# CH32V203G6U6 register map
Vendor: WCH; File version: 0.1.0
CPU: QingKe V4B V4B, little endian, no MPU, no FPU, vendor SysTick, 4 interrupt priority bits
Registers are 16-bit, read-write, reset 0x0 unless marked. A register's access mark holds for its fields unless they carry their own. Offsets are from the block's base; [hi:lo] are bit positions; {n}, {i} and the like mark numbered series.

## BKP — Backup register block
Base 0x40006C00
{0x0+4i} DATAR{i} (i=1..10) — Backup data register (BKP_DR)
  [15:0] D — Backup data
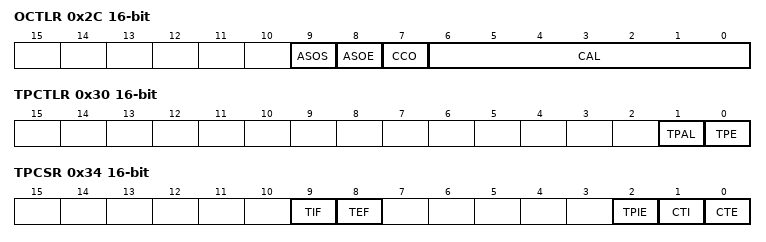
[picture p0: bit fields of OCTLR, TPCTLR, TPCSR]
0x2C OCTLR — RTC clock calibration register (BKP_OCTLR)
  [9] ASOS — Alarm or second output selection
  [8] ASOE — Alarm or second output enable
  [7] CCO — Calibration Clock Output
  [6:0] CAL — Calibration value
0x30 TPCTLR — Backup control register (BKP_TPCTLR)
  [1] TPAL — Tamper pin active level
  [0] TPE — Tamper pin enable
0x34 TPCSR — BKP_TPCSR control/status register (BKP_CSR)
  [9] TIF ro — Tamper Interrupt Flag
  [8] TEF ro — Tamper Event Flag
  [2] TPIE — Tamper Pin interrupt enable
  [1] CTI wo — Clear Tamper Interrupt
  [0] CTE wo — Clear Tamper event
{0x14+4i} DATAR{i} (i=11..42) — Backup data register (BKP_DR)
  [15:0] D — Backup data

## PWR — Power control block
Base 0x40007000
0x00 CTLR 32-bit — Power control register (PWR_CTRL)
  [8] DBP — Disable Backup Domain write protection
  [7] PLS_2V6
  [6] PLS_2V4
  [7:6] PLS_2V8
  [7:5] PLS — PVD Level Selection
  [5] PLS_2V3
  [6:5] PLS_2V5
  [7:5] PLS_2V9
  [4] PVDE — Power Voltage Detector Enable
  [3] CSBF — Clear STANDBY Flag
  [2] CWUF — Clear Wake-up Flag
  [1] PDDS — Power Down Deep Sleep
  [0] LPDS — Low Power Deep Sleep
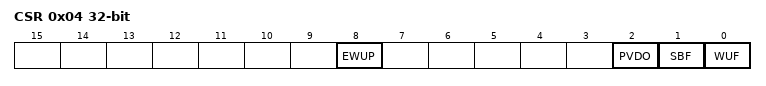
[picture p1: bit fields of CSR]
0x04 CSR 32-bit — Power control register (PWR_CSR)
  [8] EWUP — Enable WKUP pin
  [2] PVDO ro — PVD Output
  [1] SBF ro — STANDBY Flag
  [0] WUF ro — Wake-Up Flag

## AFIO — Alternate-function and pin remap controller
Base 0x40010000
0x00 ECR 32-bit — Event Control Register (AFIO_ECR)
  [26] PCFR1_SWJ_CFG_DISABLE
  [25] PCFR1_SWJ_CFG_JTAGDISABLE
  [26:24] PCFR1_SWJ_CFG
  [24] PCFR1_SWJ_CFG_NOJNTRST
  [20] PCFR1_ADC2_ETRGREG_REMAP
  [19] PCFR1_ADC2_ETRGINJ_REMAP
  [18] PCFR1_ADC1_ETRGREG_REMAP
  [17] PCFR1_ADC1_ETRGINJ_REMAP
  [16] PCFR1_TIM5CH4_IREMAP
  [15] PCFR1_PD01_REMAP
  [14] PCFR1_CAN_REMAP_REMAP2
  [14:13] PCFR1_CAN_REMAP
  [14:13] PCFR1_CAN_REMAP_REMAP3
  [12] PCFR1_TIM4_REMAP
  [11] PCFR1_TIM3_REMAP_PARTIALREMAP
  [11:10] PCFR1_TIM3_REMAP
  [11:10] PCFR1_TIM3_REMAP_FULLREMAP
  [9] PCFR1_TIM2_REMAP_PARTIALREMAP2
  [9:8] PCFR1_TIM2_REMAP
  [8] PCFR1_TIM2_REMAP_PARTIALREMAP1
  [9:8] PCFR1_TIM2_REMAP_FULLREMAP
  [7] EVOE — Event Output Enable
  [6] PORT_PE
  [7:6] PCFR1_TIM1_REMAP
  [7:6] PCFR1_TIM1_REMAP_FULLREMAP
  [5] PORT_PC
  [6:4] PORT — Port selection
  [4] PORT_PB
  [5:4] PORT_PD
  [3] PIN_PX8
  [2] PIN_PX4
  [3:2] PIN_PX12
  [1] PIN_PX2
  [2:1] PIN_PX6
  [3:1] PIN_PX14
  [3:0] PIN — Pin selection
  [0] PIN_PX1
  [1:0] PIN_PX3
  [2:0] PIN_PX7
  [3:0] PIN_PX15
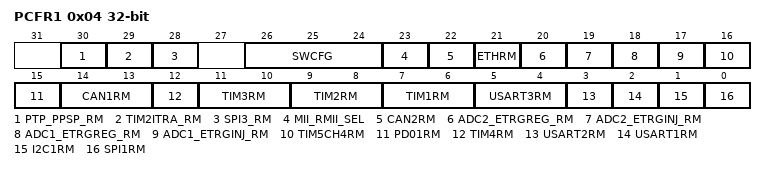
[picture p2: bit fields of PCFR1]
0x04 PCFR1 32-bit reset not defined — AF remap and debug I/O configuration register (AFIO_PCFR)
  [30] PTP_PPSP_RM — Ethernet PTP_PPS remapping
  [29] TIM2ITRA_RM — TIM2 internally triggers 1 remapping
  [28] SPI3_RM — SPI3 remapping
  [26:24] SWCFG wo — Serial wire JTAG configuration
  [23] MII_RMII_SEL
  [22] CAN2RM — CAN2 remapping
  [21] ETHRM — Ethernet remapping
  [20] ADC2_ETRGREG_RM — ADC 2 external trigger regular conversion remapping
  [19] ADC2_ETRGINJ_RM — ADC 2 External trigger injected conversion remapping
  [18] ADC1_ETRGREG_RM — ADC 1 external trigger regular conversion remapping
  [17] ADC1_ETRGINJ_RM — ADC 1 External trigger injected conversion remapping
  [16] TIM5CH4RM — TIM5 channel4 internal remap
  [15] PD01RM — Port D0/Port D1 mapping on OSCIN/OSCOUT
  [14:13] CAN1RM — CAN1 remapping
  [12] TIM4RM — TIM4 remapping
  [11:10] TIM3RM — TIM3 remapping
  [9:8] TIM2RM — TIM2 remapping
  [7:6] TIM1RM — TIM1 remapping
  [5:4] USART3RM — USART3 remapping
  [3] USART2RM — USART2 remapping
  [2] USART1RM — USART1 remapping
  [1] I2C1RM — I2C1 remapping
  [0] SPI1RM — SPI1 remapping
0x08 EXTICR1 32-bit — External interrupt configuration register 1 (AFIO_EXTICR1)
  [4n+2] EXTI{n}_PE (n=0..3)
  [4n+1] EXTI{n}_PC (n=0..3)
  [4n+2:4n+1] EXTI{n}_PG (n=0..3)
  [4n+3:4n] EXTI{n} (n=0..3) — EXTI{n} configuration
  [4n] EXTI{n}_PB (n=0..3)
  [4n+1:4n] EXTI{n}_PD (n=0..3)
0x0C EXTICR2 32-bit — External interrupt configuration register 2 (AFIO_EXTICR2)
  [4n-14] EXTI{n}_PE (n=4..7)
  [4n-15] EXTI{n}_PC (n=4..7)
  [4n-14:4n-15] EXTI{n}_PG (n=4..7)
  [4n-13:4n-16] EXTI{n} (n=4..7) — EXTI{n} configuration
  [4n-16] EXTI{n}_PB (n=4..7)
  [4n-15:4n-16] EXTI{n}_PD (n=4..7)
0x10 EXTICR3 32-bit — External interrupt configuration register 3 (AFIO_EXTICR3)
  [4n-30] EXTI{n}_PE (n=8..11)
  [4n-31] EXTI{n}_PC (n=8..11)
  [4n-30:4n-31] EXTI{n}_PG (n=8..11)
  [4n-29:4n-32] EXTI{n} (n=8..11) — EXTI{n} configuration
  [4n-32] EXTI{n}_PB (n=8..11)
  [4n-31:4n-32] EXTI{n}_PD (n=8..11)
0x14 EXTICR4 32-bit — External interrupt configuration register 4 (AFIO_EXTICR4)
  [4n-46] EXTI{n}_PE (n=12..15)
  [4n-47] EXTI{n}_PC (n=12..15)
  [4n-46:4n-47] EXTI{n}_PG (n=12..15)
  [4n-45:4n-48] EXTI{n} (n=12..15) — EXTI{n} configuration
  [4n-48] EXTI{n}_PB (n=12..15)
  [4n-47:4n-48] EXTI{n}_PD (n=12..15)
0x1C PCFR2 32-bit — AF remap and debug I/O configuration register (AFIO_PCFR2)
  [27:26] USART4_RM — USART4 remap
